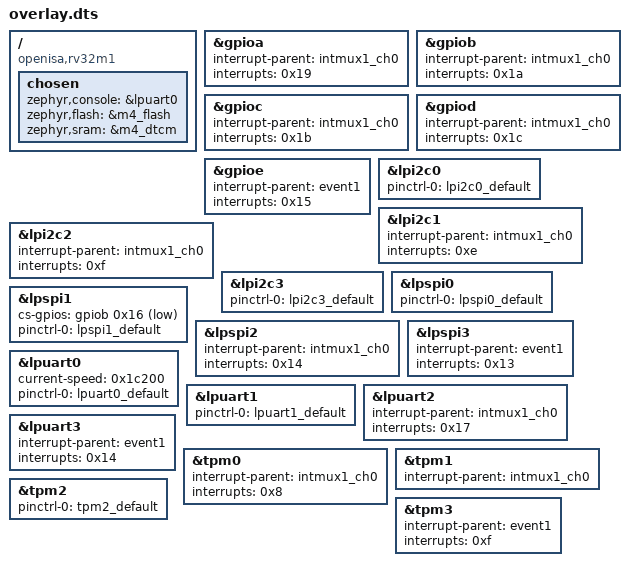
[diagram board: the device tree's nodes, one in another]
/ {
	compatible = "openisa,rv32m1";
	chosen {
		zephyr,console = &lpuart0;
		zephyr,flash = &m4_flash;
		zephyr,sram = &m4_dtcm;
	};
};
&gpioa{
	interrupt-parent = < &intmux1_ch0 >;
	interrupts = < 0x19 >;
};
&gpiob{
	interrupt-parent = < &intmux1_ch0 >;
	interrupts = < 0x1a >;
};
&gpioc{
	interrupt-parent = < &intmux1_ch0 >;
	interrupts = < 0x1b >;
};
&gpiod{
	interrupt-parent = < &intmux1_ch0 >;
	interrupts = < 0x1c >;
};
&gpioe{
	interrupt-parent = < &event1 >;
	interrupts = < 0x15 >;
};
&lpi2c0{
	status = "okay";
	pinctrl-0 = < &lpi2c0_default >;
	pinctrl-names = "default";
};
&lpi2c1{
	interrupt-parent = < &intmux1_ch0 >;
	interrupts = < 0xe >;
};
&lpi2c2{
	interrupt-parent = < &intmux1_ch0 >;
	interrupts = < 0xf >;
};
&lpi2c3{
	status = "okay";
	pinctrl-0 = < &lpi2c3_default >;
	pinctrl-names = "default";
};
&lpspi0{
	status = "okay";
	pinctrl-0 = < &lpspi0_default >;
	pinctrl-names = "default";
};
&lpspi1{
	status = "okay";
	cs-gpios = < &gpiob 0x16 0x1 >;
	pinctrl-0 = < &lpspi1_default >;
	pinctrl-names = "default";
};
&lpspi2{
	interrupt-parent = < &intmux1_ch0 >;
	interrupts = < 0x14 >;
};
&lpspi3{
	interrupt-parent = < &event1 >;
	interrupts = < 0x13 >;
};
&lpuart0{
	status = "okay";
	current-speed = < 0x1c200 >;
	pinctrl-0 = < &lpuart0_default >;
	pinctrl-names = "default";
};
&lpuart1{
	pinctrl-0 = < &lpuart1_default >;
	pinctrl-names = "default";
};
&lpuart2{
	interrupt-parent = < &intmux1_ch0 >;
	interrupts = < 0x17 >;
};
&lpuart3{
	interrupt-parent = < &event1 >;
	interrupts = < 0x14 >;
};
&tpm0{
	interrupt-parent = < &intmux1_ch0 >;
	interrupts = < 0x8 >;
};
&tpm1{
	interrupt-parent = < &intmux1_ch0 >;
};
&tpm2{
	status = "okay";
	pinctrl-0 = < &tpm2_default >;
	pinctrl-names = "default";
};
&tpm3{
	interrupt-parent = < &event1 >;
	interrupts = < 0xf >;
};
